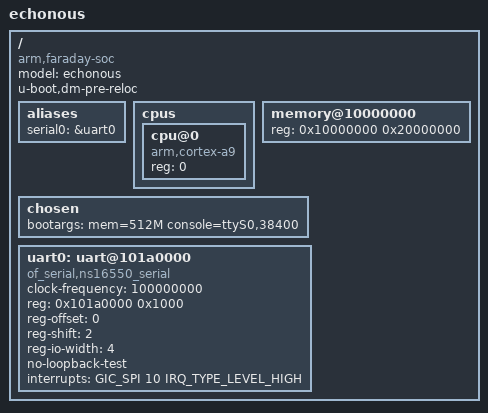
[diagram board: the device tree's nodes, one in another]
/*
 * Copyright (C) 2014 Faraday, Inc. (www.faraday-tech.com)
 *
 * This program is free software; you can redistribute it and/or modify
 * it under the terms of the GNU General Public License version 2 as
 * published by the Free Software Foundation.
 */
 /dts-v1/;
#include <dt-bindings/interrupt-controller/arm-gic.h>
/  {
	model = "echonous";
	compatible = "arm,faraday-soc";
    u-boot,dm-pre-reloc;
	#address-cells = <1>;
	#size-cells = <1>;
	
	aliases {
		serial0 = &uart0;
	};
	
	cpus {
		#address-cells = <1>;
		#size-cells = <0>;

		cpu@0 {
			device_type = "cpu";
			compatible = "arm,cortex-a9";
			reg = <0>;
		};
	};

	memory@10000000 {
		device_type = "memory";
		reg = <0x10000000 0x20000000>;
	};
		
	
	chosen {
		bootargs = "mem=512M console=ttyS0,38400";
	};
		
	uart0: uart@101a0000 {
		compatible = "of_serial,ns16550_serial", "ns16550a";
		clock-frequency = <100000000>;
		reg = <0x101a0000 0x1000>;
		reg-offset = <0>;
		reg-shift = <2>;
		reg-io-width = <4>;		
		no-loopback-test;
		interrupts = <GIC_SPI 10 IRQ_TYPE_LEVEL_HIGH>;
	};

};
